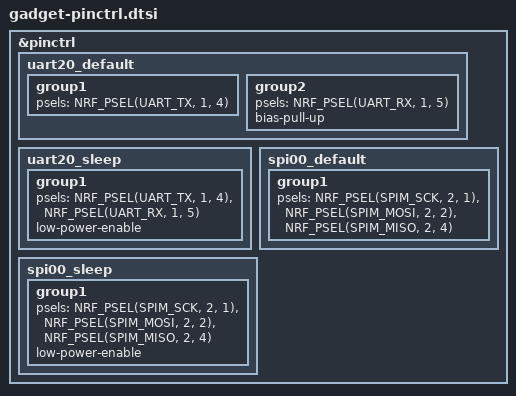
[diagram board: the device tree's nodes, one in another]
/*
 * Gadget rev A provisional pin assignments.
 *
 * The schematic is still in progress; these pins are placeholders chosen
 * from the nRF54L15 QFN48 GPIO0/GPIO1/GPIO2 banks and must be re-checked
 * against the finished schematic before rev A is fabricated.
 */

&pinctrl {
	/omit-if-no-ref/ uart20_default: uart20_default {
		group1 {
			psels = <NRF_PSEL(UART_TX, 1, 4)>;
		};

		group2 {
			psels = <NRF_PSEL(UART_RX, 1, 5)>;
			bias-pull-up;
		};
	};

	/omit-if-no-ref/ uart20_sleep: uart20_sleep {
		group1 {
			psels = <NRF_PSEL(UART_TX, 1, 4)>,
				<NRF_PSEL(UART_RX, 1, 5)>;
			low-power-enable;
		};
	};

	/omit-if-no-ref/ spi00_default: spi00_default {
		group1 {
			psels = <NRF_PSEL(SPIM_SCK, 2, 1)>,
				<NRF_PSEL(SPIM_MOSI, 2, 2)>,
				<NRF_PSEL(SPIM_MISO, 2, 4)>;
		};
	};

	/omit-if-no-ref/ spi00_sleep: spi00_sleep {
		group1 {
			psels = <NRF_PSEL(SPIM_SCK, 2, 1)>,
				<NRF_PSEL(SPIM_MOSI, 2, 2)>,
				<NRF_PSEL(SPIM_MISO, 2, 4)>;
			low-power-enable;
		};
	};
};
